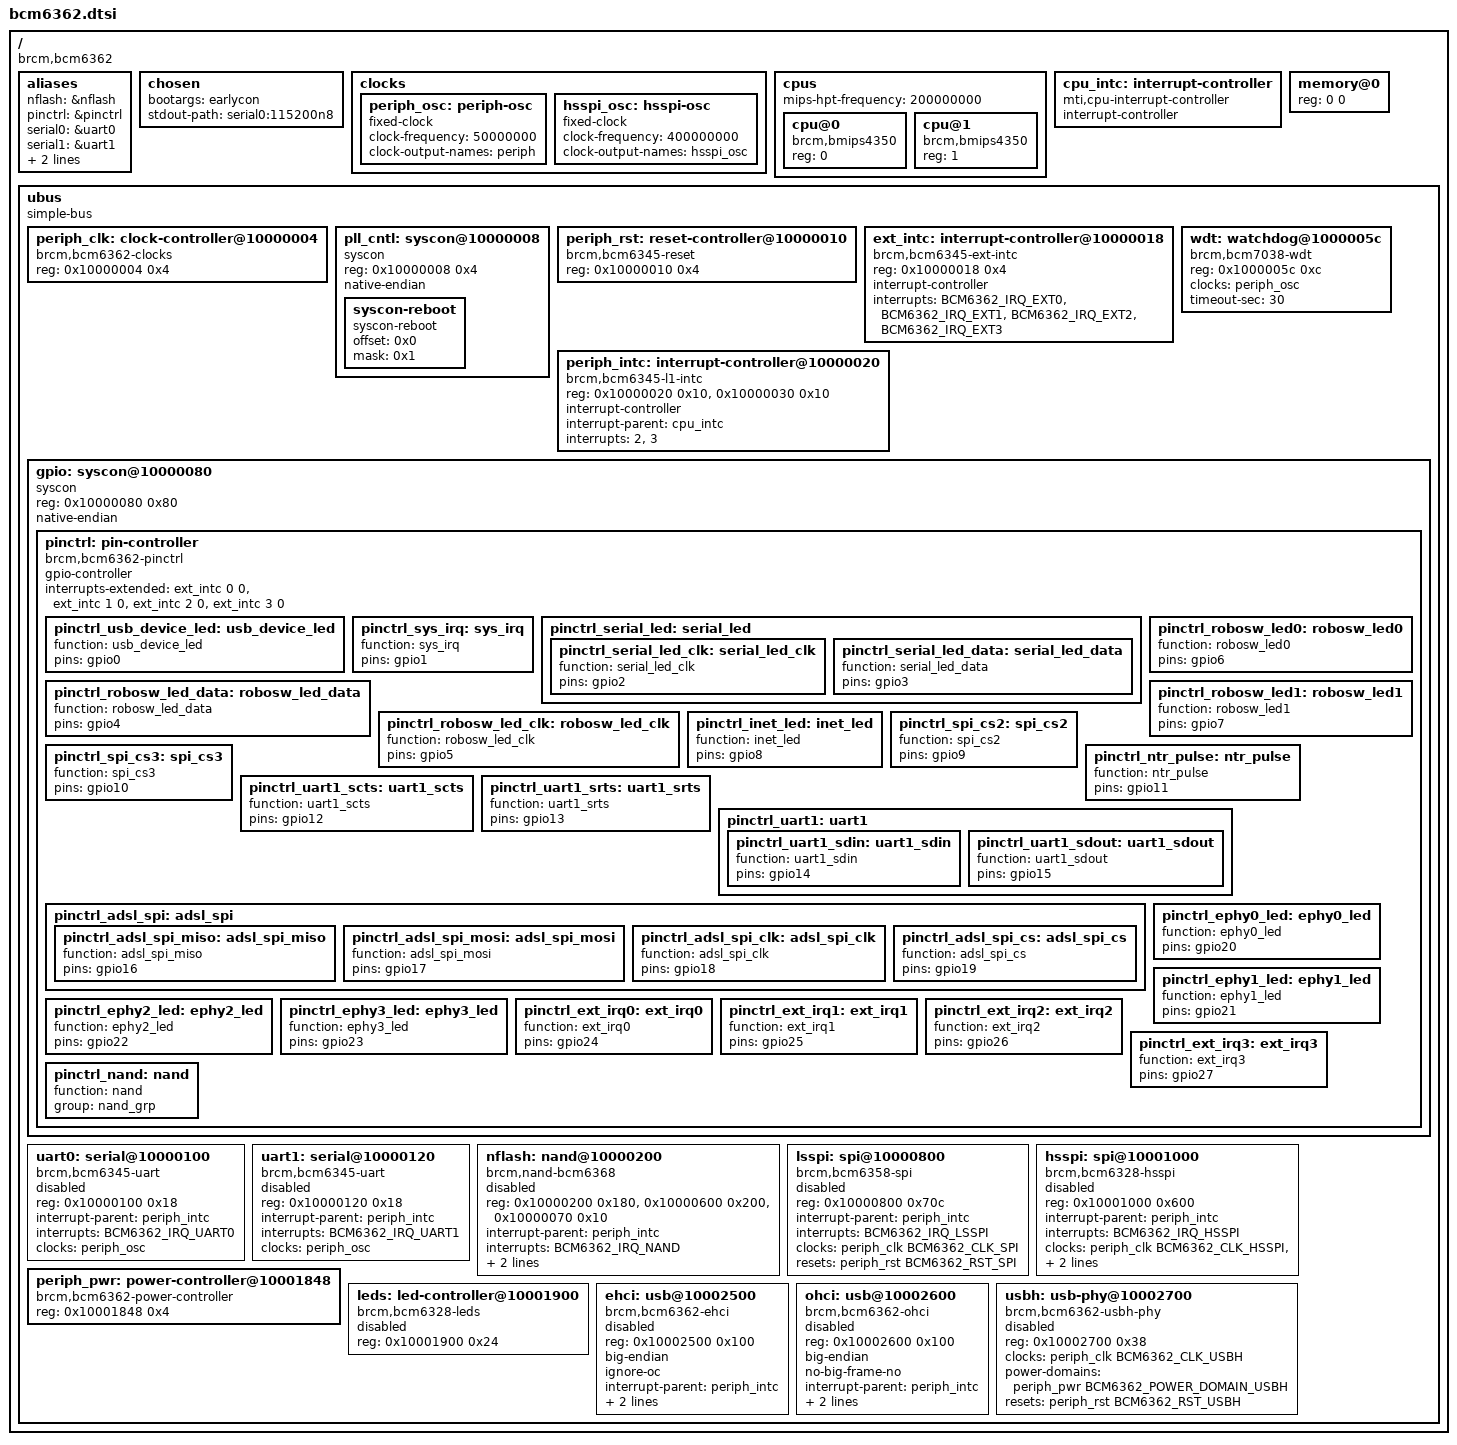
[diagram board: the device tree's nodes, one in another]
// SPDX-License-Identifier: GPL-2.0-or-later

/dts-v1/;

#include <dt-bindings/clock/bcm6362-clock.h>
#include <dt-bindings/gpio/gpio.h>
#include <dt-bindings/input/input.h>
#include <dt-bindings/interrupt-controller/bcm6362-interrupt-controller.h>
#include <dt-bindings/reset/bcm6362-reset.h>
#include <dt-bindings/soc/bcm6362-pm.h>

/ {
	#address-cells = <1>;
	#size-cells = <1>;
	compatible = "brcm,bcm6362";

	aliases {
		nflash = &nflash;
		pinctrl = &pinctrl;
		serial0 = &uart0;
		serial1 = &uart1;
		spi0 = &lsspi;
		spi1 = &hsspi;
	};

	chosen {
		bootargs = "earlycon";
		stdout-path = "serial0:115200n8";
	};

	clocks {
		periph_osc: periph-osc {
			compatible = "fixed-clock";

			#clock-cells = <0>;

			clock-frequency = <50000000>;
			clock-output-names = "periph";
		};

		hsspi_osc: hsspi-osc {
			compatible = "fixed-clock";

			#clock-cells = <0>;

			clock-frequency = <400000000>;
			clock-output-names = "hsspi_osc";
		};
	};

	cpus {
		#address-cells = <1>;
		#size-cells = <0>;
		mips-hpt-frequency = <200000000>;

		cpu@0 {
			compatible = "brcm,bmips4350", "mips,mips4Kc";
			device_type = "cpu";
			reg = <0>;
		};

		cpu@1 {
			compatible = "brcm,bmips4350", "mips,mips4Kc";
			device_type = "cpu";
			reg = <1>;
		};
	};

	cpu_intc: interrupt-controller {
		#address-cells = <0>;
		compatible = "mti,cpu-interrupt-controller";

		interrupt-controller;
		#interrupt-cells = <1>;
	};

	memory@0 {
		device_type = "memory";
		reg = <0 0>;
	};

	ubus {
		#address-cells = <1>;
		#size-cells = <1>;

		compatible = "simple-bus";
		ranges;

		periph_clk: clock-controller@10000004 {
			compatible = "brcm,bcm6362-clocks";
			reg = <0x10000004 0x4>;
			#clock-cells = <1>;
		};

		pll_cntl: syscon@10000008 {
			compatible = "syscon", "simple-mfd";
			reg = <0x10000008 0x4>;
			native-endian;

			syscon-reboot {
				compatible = "syscon-reboot";
				offset = <0x0>;
				mask = <0x1>;
			};
		};

		periph_rst: reset-controller@10000010 {
			compatible = "brcm,bcm6345-reset";
			reg = <0x10000010 0x4>;
			#reset-cells = <1>;
		};

		ext_intc: interrupt-controller@10000018 {
			#address-cells = <1>;
			compatible = "brcm,bcm6345-ext-intc";
			reg = <0x10000018 0x4>;

			interrupt-controller;
			#interrupt-cells = <2>;

			interrupts = <BCM6362_IRQ_EXT0>,
				     <BCM6362_IRQ_EXT1>,
				     <BCM6362_IRQ_EXT2>,
				     <BCM6362_IRQ_EXT3>;
		};

		periph_intc: interrupt-controller@10000020 {
			#address-cells = <1>;
			compatible = "brcm,bcm6345-l1-intc";
			reg = <0x10000020 0x10>,
			      <0x10000030 0x10>;

			interrupt-controller;
			#interrupt-cells = <1>;

			interrupt-parent = <&cpu_intc>;
			interrupts = <2>, <3>;
		};

		wdt: watchdog@1000005c {
			compatible = "brcm,bcm7038-wdt";
			reg = <0x1000005c 0xc>;

			clocks = <&periph_osc>;

			timeout-sec = <30>;
		};

		gpio: syscon@10000080 {
			compatible = "syscon", "simple-mfd";
			reg = <0x10000080 0x80>;
			native-endian;

			pinctrl: pin-controller {
				compatible = "brcm,bcm6362-pinctrl";

				gpio-controller;
				#gpio-cells = <2>;

				interrupts-extended = <&ext_intc 0 0>,
						      <&ext_intc 1 0>,
						      <&ext_intc 2 0>,
						      <&ext_intc 3 0>;
				interrupt-names = "gpio24",
						  "gpio25",
						  "gpio26",
						  "gpio27";

				pinctrl_usb_device_led: usb_device_led {
					function = "usb_device_led";
					pins = "gpio0";
				};

				pinctrl_sys_irq: sys_irq {
					function = "sys_irq";
					pins = "gpio1";
				};

				pinctrl_serial_led: serial_led {
					pinctrl_serial_led_clk: serial_led_clk {
						function = "serial_led_clk";
						pins = "gpio2";
					};

					pinctrl_serial_led_data: serial_led_data {
						function = "serial_led_data";
						pins = "gpio3";
					};
				};

				pinctrl_robosw_led_data: robosw_led_data {
					function = "robosw_led_data";
					pins = "gpio4";
				};

				pinctrl_robosw_led_clk: robosw_led_clk {
					function = "robosw_led_clk";
					pins = "gpio5";
				};

				pinctrl_robosw_led0: robosw_led0 {
					function = "robosw_led0";
					pins = "gpio6";
				};

				pinctrl_robosw_led1: robosw_led1 {
					function = "robosw_led1";
					pins = "gpio7";
				};

				pinctrl_inet_led: inet_led {
					function = "inet_led";
					pins = "gpio8";
				};

				pinctrl_spi_cs2: spi_cs2 {
					function = "spi_cs2";
					pins = "gpio9";
				};

				pinctrl_spi_cs3: spi_cs3 {
					function = "spi_cs3";
					pins = "gpio10";
				};

				pinctrl_ntr_pulse: ntr_pulse {
					function = "ntr_pulse";
					pins = "gpio11";
				};

				pinctrl_uart1_scts: uart1_scts {
					function = "uart1_scts";
					pins = "gpio12";
				};

				pinctrl_uart1_srts: uart1_srts {
					function = "uart1_srts";
					pins = "gpio13";
				};

				pinctrl_uart1: uart1 {
					pinctrl_uart1_sdin: uart1_sdin {
						function = "uart1_sdin";
						pins = "gpio14";
					};

					pinctrl_uart1_sdout: uart1_sdout {
						function = "uart1_sdout";
						pins = "gpio15";
					};
				};

				pinctrl_adsl_spi: adsl_spi {
					pinctrl_adsl_spi_miso: adsl_spi_miso {
						function = "adsl_spi_miso";
						pins = "gpio16";
					};

					pinctrl_adsl_spi_mosi: adsl_spi_mosi {
						function = "adsl_spi_mosi";
						pins = "gpio17";
					};

					pinctrl_adsl_spi_clk: adsl_spi_clk {
						function = "adsl_spi_clk";
						pins = "gpio18";
					};

					pinctrl_adsl_spi_cs: adsl_spi_cs {
						function = "adsl_spi_cs";
						pins = "gpio19";
					};
				};

				pinctrl_ephy0_led: ephy0_led {
					function = "ephy0_led";
					pins = "gpio20";
				};

				pinctrl_ephy1_led: ephy1_led {
					function = "ephy1_led";
					pins = "gpio21";
				};

				pinctrl_ephy2_led: ephy2_led {
					function = "ephy2_led";
					pins = "gpio22";
				};

				pinctrl_ephy3_led: ephy3_led {
					function = "ephy3_led";
					pins = "gpio23";
				};

				pinctrl_ext_irq0: ext_irq0 {
					function = "ext_irq0";
					pins = "gpio24";
				};

				pinctrl_ext_irq1: ext_irq1 {
					function = "ext_irq1";
					pins = "gpio25";
				};

				pinctrl_ext_irq2: ext_irq2 {
					function = "ext_irq2";
					pins = "gpio26";
				};

				pinctrl_ext_irq3: ext_irq3 {
					function = "ext_irq3";
					pins = "gpio27";
				};

				pinctrl_nand: nand {
					function = "nand";
					group = "nand_grp";
				};
			};
		};

		uart0: serial@10000100 {
			compatible = "brcm,bcm6345-uart";
			reg = <0x10000100 0x18>;

			interrupt-parent = <&periph_intc>;
			interrupts = <BCM6362_IRQ_UART0>;

			clocks = <&periph_osc>;
			clock-names = "periph";

			status = "disabled";
		};

		uart1: serial@10000120 {
			compatible = "brcm,bcm6345-uart";
			reg = <0x10000120 0x18>;

			interrupt-parent = <&periph_intc>;
			interrupts = <BCM6362_IRQ_UART1>;

			clocks = <&periph_osc>;
			clock-names = "periph";

			status = "disabled";
		};

		nflash: nand@10000200 {
			#address-cells = <1>;
			#size-cells = <0>;
			compatible = "brcm,nand-bcm6368",
				     "brcm,brcmnand-v2.2",
				     "brcm,brcmnand";
			reg = <0x10000200 0x180>,
			      <0x10000600 0x200>,
			      <0x10000070 0x10>;
			reg-names = "nand",
				    "nand-cache",
				    "nand-int-base";

			interrupt-parent = <&periph_intc>;
			interrupts = <BCM6362_IRQ_NAND>;

			clocks = <&periph_clk BCM6362_CLK_NAND>;
			clock-names = "nand";

			pinctrl-names = "default";
			pinctrl-0 = <&pinctrl_nand>;

			status = "disabled";
		};

		lsspi: spi@10000800 {
			compatible = "brcm,bcm6358-spi";
			reg = <0x10000800 0x70c>;
			#address-cells = <1>;
			#size-cells = <0>;

			interrupt-parent = <&periph_intc>;
			interrupts = <BCM6362_IRQ_LSSPI>;

			clocks = <&periph_clk BCM6362_CLK_SPI>;
			clock-names = "spi";

			resets = <&periph_rst BCM6362_RST_SPI>;

			status = "disabled";
		};

		hsspi: spi@10001000 {
			compatible = "brcm,bcm6328-hsspi";
			reg = <0x10001000 0x600>;
			#address-cells = <1>;
			#size-cells = <0>;

			interrupt-parent = <&periph_intc>;
			interrupts = <BCM6362_IRQ_HSSPI>;

			clocks = <&periph_clk BCM6362_CLK_HSSPI>,
				 <&hsspi_osc>;
			clock-names = "hsspi",
				      "pll";

			resets = <&periph_rst BCM6362_RST_SPI>;

			status = "disabled";
		};

		periph_pwr: power-controller@10001848 {
			compatible = "brcm,bcm6362-power-controller";
			reg = <0x10001848 0x4>;
			#power-domain-cells = <1>;
		};

		leds: led-controller@10001900 {
			#address-cells = <1>;
			#size-cells = <0>;
			compatible = "brcm,bcm6328-leds";
			reg = <0x10001900 0x24>;

			status = "disabled";
		};

		ehci: usb@10002500 {
			compatible = "brcm,bcm6362-ehci", "generic-ehci";
			reg = <0x10002500 0x100>;
			big-endian;
			ignore-oc;

			interrupt-parent = <&periph_intc>;
			interrupts = <BCM6362_IRQ_EHCI>;

			phys = <&usbh 0>;
			phy-names = "usb";

			status = "disabled";
		};

		ohci: usb@10002600 {
			compatible = "brcm,bcm6362-ohci", "generic-ohci";
			reg = <0x10002600 0x100>;
			big-endian;
			no-big-frame-no;

			interrupt-parent = <&periph_intc>;
			interrupts = <BCM6362_IRQ_OHCI>;

			phys = <&usbh 0>;
			phy-names = "usb";

			status = "disabled";
		};

		usbh: usb-phy@10002700 {
			compatible = "brcm,bcm6362-usbh-phy";
			reg = <0x10002700 0x38>;

			#phy-cells = <1>;

			clocks = <&periph_clk BCM6362_CLK_USBH>;
			clock-names = "usbh";

			power-domains = <&periph_pwr BCM6362_POWER_DOMAIN_USBH>;
			resets = <&periph_rst BCM6362_RST_USBH>;

			status = "disabled";
		};
	};
};
